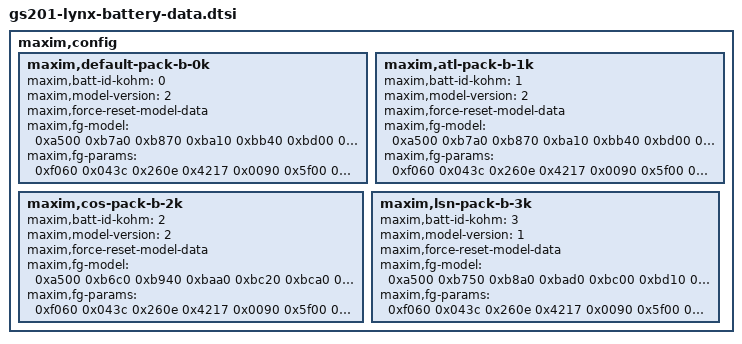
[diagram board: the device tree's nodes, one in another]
// SPDX-License-Identifier: GPL-2.0-only
/*
 * Battery device tree entries
 *
 * Copyright 2022 Google LLC
 *
 */

maxim,config {
	maxim,default-pack-b-0k {
		maxim,batt-id-kohm = <0>;
		maxim,model-version = <2>;
		maxim,force-reset-model-data;
		maxim,fg-model = /bits/ 16 <
			0xa500 0xb7a0 0xb870 0xba10 0xbb40 0xbd00 0xbe40 0xbfe0
			0xc230 0xc430 0xc720 0xca00 0xcdc0 0xd180 0xd5d0 0xdd90
			0x01b0 0x1600 0x0c00 0x0d00 0x1700 0x1300 0x1200 0x0f20
			0x07d0 0x07f0 0x0810 0x06e0 0x06f0 0x07f0 0x04f0 0x04f0
			0x0200 0x0200 0x0200 0x0200 0x0200 0x0200 0x0200 0x0200
			0x0200 0x0200 0x0200 0x0200 0x0200 0x0200 0x0200 0x0200
		>;
		maxim,fg-params = /bits/ 16 <
			/* 0x0036 */	0xf060	/* nIAvgEmpty -> IAvgEmpty */
			/* 0x002a */	0x043c	/* nRelaxCFG -> RelaxCFG */
			/* 0x0028 */	0x260e	/* nLearnCFG -> LearnCFG */
			/* 0x001D */	0x4217	/* Config: */
			/* 0x00BB */	0x0090	/* Config2: OCVQen|DSOCIi */
			/* 0x0013 */	0x5f00	/* nFullSOCThr -> FullSOCThr*/
			/* 0x0035 */	0x088d	/* nFullCapRep */
			/* 0x0018 */	0x088d	/* nDesignCap */
			/* 0x0046 */	0x3200	/* dPacc */
			/* 0x0045 */	0x0223	/* dQacc */
			/* 0x0023 */	0x088d	/* nFullCapNom */
			/* 0x003A */	0xA561	/* V_empty */
			/* 0x0012 */	0x1680	/* nQRTable00 -> QResidual00 */
			/* 0x0022 */	0x0b80	/* nQRTable10 -> QResidual10 */
			/* 0x0032 */	0x0680	/* nQRTable20 -> QResidual20 */
			/* 0x0042 */	0x0500	/* nQRTable30 -> QResidual30 */
			/* 0x0038 */	0x0460	/* nRcomp0 */
			/* 0x0039 */	0x0902	/* nTempco */
			/* 0x001E */	0x0560	/* ICHGTerm */
			/* 0x002C */	0xED51	/* *TGain */
			/* 0x002D */	0x1EBA	/* *TOFF */
			/* 0x00B9 */	0x0014	/* *TCurve */
			/* 0x002B */	0x3870	/* *nMiscCfg */
			/* 0x0004 */	0x1900	/* AtRate @ 0x04 */
			/* 0x0049 */	0x2241	/* convgcfg */
			/* 0x0029 */	0xc615	/* FilterCFG */
			/* 0x003c */	0x2D00	/* TaskPeriod */
			/* 0x002e */	0x0400	/* CGain */
		>;
	};
	/* 1_L10_ATL_031522_RC2_INI_0411.txt http://b/222021712#comment5 */
	maxim,atl-pack-b-1k {
		maxim,batt-id-kohm = <1>;
		maxim,model-version = <2>;
		maxim,force-reset-model-data;
		maxim,fg-model = /bits/ 16 <
			0xa500 0xb7a0 0xb870 0xba10 0xbb40 0xbd00 0xbe40 0xbfe0
			0xc230 0xc430 0xc720 0xca00 0xcdc0 0xd180 0xd5d0 0xdd90
			0x01b0 0x1600 0x0c00 0x0d00 0x1700 0x1300 0x1200 0x0f20
			0x07d0 0x07f0 0x0810 0x06e0 0x06f0 0x07f0 0x04f0 0x04f0
			0x0200 0x0200 0x0200 0x0200 0x0200 0x0200 0x0200 0x0200
			0x0200 0x0200 0x0200 0x0200 0x0200 0x0200 0x0200 0x0200
		>;
		maxim,fg-params = /bits/ 16 <
			/* 0x0036 */	0xf060	/* nIAvgEmpty -> IAvgEmpty */
			/* 0x002a */	0x043c	/* nRelaxCFG -> RelaxCFG */
			/* 0x0028 */	0x260e	/* nLearnCFG -> LearnCFG */
			/* 0x001D */	0x4217	/* Config: */
			/* 0x00BB */	0x0090	/* Config2: OCVQen|DSOCIi */
			/* 0x0013 */	0x5f00	/* nFullSOCThr -> FullSOCThr*/
			/* 0x0035 */	0x088d	/* nFullCapRep */
			/* 0x0018 */	0x088d	/* nDesignCap */
			/* 0x0046 */	0x3200	/* dPacc */
			/* 0x0045 */	0x0223	/* dQacc */
			/* 0x0023 */	0x088d	/* nFullCapNom */
			/* 0x003A */	0xA561	/* V_empty */
			/* 0x0012 */	0x1680	/* nQRTable00 -> QResidual00 */
			/* 0x0022 */	0x0b80	/* nQRTable10 -> QResidual10 */
			/* 0x0032 */	0x0680	/* nQRTable20 -> QResidual20 */
			/* 0x0042 */	0x0500	/* nQRTable30 -> QResidual30 */
			/* 0x0038 */	0x0460	/* nRcomp0 */
			/* 0x0039 */	0x0902	/* nTempco */
			/* 0x001E */	0x0560	/* ICHGTerm */
			/* 0x002C */	0xED51	/* *TGain */
			/* 0x002D */	0x1EBA	/* *TOFF */
			/* 0x00B9 */	0x0014	/* *TCurve */
			/* 0x002B */	0x3870	/* *nMiscCfg */
			/* 0x0004 */	0x1900	/* AtRate @ 0x04 */
			/* 0x0049 */	0x2241	/* convgcfg */
			/* 0x0029 */	0xc615	/* FilterCFG */
			/* 0x003c */	0x2D00	/* TaskPeriod */
			/* 0x002e */	0x0400	/* CGain */
		>;
	};
	/* 2_L10_COS_031622_RC2_INI_0411.txt http://b/222021712#comment5 */
	maxim,cos-pack-b-2k {
		maxim,batt-id-kohm = <2>;
		maxim,model-version = <2>;
		maxim,force-reset-model-data;
		maxim,fg-model = /bits/ 16 <
			0xa500 0xb6c0 0xb940 0xbaa0 0xbc20 0xbca0 0xbed0 0xc010
			0xc190 0xc430 0xc7c0 0xcac0 0xcdf0 0xd160 0xd5b0 0xddb0
			0x01d0 0x0810 0x1100 0x1300 0x1900 0x1300 0x1400 0x0e30
			0x0a10 0x0710 0x06e0 0x07f0 0x06f0 0x07f0 0x04f0 0x04f0
			0x0200 0x0200 0x0200 0x0200 0x0200 0x0200 0x0200 0x0200
			0x0200 0x0200 0x0200 0x0200 0x0200 0x0200 0x0200 0x0200
		>;
		maxim,fg-params = /bits/ 16 <
			/* 0x0036 */	0xf060	/* nIAvgEmpty -> IAvgEmpty */
			/* 0x002a */	0x043c	/* nRelaxCFG -> RelaxCFG */
			/* 0x0028 */	0x260e	/* nLearnCFG -> LearnCFG */
			/* 0x001D */	0x4217	/* Config: */
			/* 0x00BB */	0x0090	/* Config2: OCVQen|DSOCIi */
			/* 0x0013 */	0x5f00	/* nFullSOCThr -> FullSOCThr*/
			/* 0x0035 */	0x08A2	/* nFullCapRep */
			/* 0x0018 */	0x08A2	/* nDesignCap */
			/* 0x0046 */	0x3200	/* dPacc */
			/* 0x0045 */	0x0228	/* dQacc */
			/* 0x0023 */	0x08A2	/* nFullCapNom */
			/* 0x003A */	0xA561	/* V_empty */
			/* 0x0012 */	0x1900	/* nQRTable00 -> QResidual00 */
			/* 0x0022 */	0x1100	/* nQRTable10 -> QResidual10 */
			/* 0x0032 */	0x0d80	/* nQRTable20 -> QResidual20 */
			/* 0x0042 */	0x0a80	/* nQRTable30 -> QResidual30 */
			/* 0x0038 */	0x07a0	/* nRcomp0 */
			/* 0x0039 */	0x0902	/* nTempco */
			/* 0x001E */	0x0560	/* ICHGTerm */
			/* 0x002C */	0xED51	/* *TGain */
			/* 0x002D */	0x1EBA	/* *TOFF */
			/* 0x00B9 */	0x0014	/* *TCurve */
			/* 0x002B */	0x3870	/* *nMiscCfg */
			/* 0x0004 */	0x1900	/* AtRate @ 0x04 */
			/* 0x0049 */	0x2241	/* convgcfg */
			/* 0x0029 */	0xc615	/* FilterCFG */
			/* 0x003c */	0x2D00	/* TaskPeriod */
			/* 0x002e */	0x0400	/* CGain */
		>;
	};
	/* 3_B3_LSN_3114_1_092821_BC59_RC2_1028.txt http://b/204411635#comment1 */
	maxim,lsn-pack-b-3k {
		maxim,batt-id-kohm = <3>;
		maxim,model-version = <1>;
		maxim,force-reset-model-data;
		maxim,fg-model = /bits/ 16 <
			0xa500 0xb750 0xb8a0 0xbad0 0xbc00 0xbd10 0xbdf0 0xbee0
			0xc080 0xc290 0xc5d0 0xc910 0xcf30 0xd270 0xd5a0 0xdc80
			0x0110 0x1310 0x0c10 0x1400 0x1630 0x1a00 0x1800 0x10e0
			0x0cf0 0x07e0 0x07f0 0x0710 0x06b0 0x06e0 0x0660 0x0660
			0x0200 0x0200 0x0200 0x0200 0x0200 0x0200 0x0200 0x0200
			0x0200 0x0200 0x0200 0x0200 0x0200 0x0200 0x0200 0x0200
		>;
		maxim,fg-params = /bits/ 16 <
			/* 0x0036 */	0xf060	/* nIAvgEmpty -> IAvgEmpty */
			/* 0x002a */	0x043c	/* nRelaxCFG -> RelaxCFG */
			/* 0x0028 */	0x260e	/* nLearnCFG -> LearnCFG */
			/* 0x001D */	0x4217	/* Config: */
			/* 0x00BB */	0x0090	/* Config2: OCVQen|DSOCIi */
			/* 0x0013 */	0x5f00	/* nFullSOCThr -> FullSOCThr*/
			/* 0x0035 */	0x08b1	/* nFullCapRep */
			/* 0x0018 */	0x08b1	/* nDesignCap */
			/* 0x0046 */	0x3200	/* dPacc */
			/* 0x0045 */	0x022c	/* dQacc */
			/* 0x0023 */	0x08b1	/* nFullCapNom */
			/* 0x003A */	0xA561	/* V_empty */
			/* 0x0012 */	0x2500	/* nQRTable00 -> QResidual00 */
			/* 0x0022 */	0x1000	/* nQRTable10 -> QResidual10 */
			/* 0x0032 */	0x0580	/* nQRTable20 -> QResidual20 */
			/* 0x0042 */	0x0480	/* nQRTable30 -> QResidual30 */
			/* 0x0038 */	0x0720	/* nRcomp0 */
			/* 0x0039 */	0x1a02	/* nTempco */
			/* 0x001E */	0x0560	/* ICHGTerm */
			/* 0x002C */	0xED51	/* *TGain */
			/* 0x002D */	0x1EBA	/* *TOFF */
			/* 0x00B9 */	0x0014	/* *TCurve */
			/* 0x002B */	0x3870	/* *nMiscCfg */
			/* 0x0004 */	0x1900	/* AtRate @ 0x04 */
			/* 0x0049 */	0x2241	/* convgcfg */
			/* 0x0029 */	0xc615	/* FilterCFG */
			/* 0x003c */	0x2D00	/* TaskPeriod */
			/* 0x002e */	0x0400	/* CGain */
		>;
	};

};
